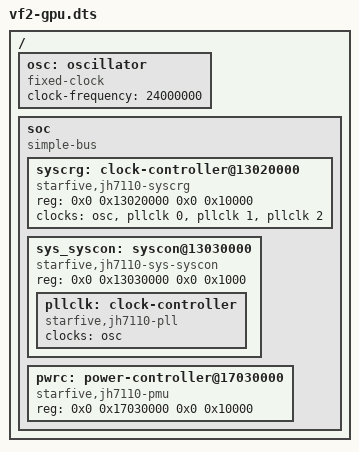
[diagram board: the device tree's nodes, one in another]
/*
 * A device tree in the shape of the VisionFive 2's for the GPU's glue:
 * the oscillator, the SYS clock generator and system control block, and
 * the power management unit.  No GPU node, as on the board.
 */
/dts-v1/;

/ {
	#address-cells = <2>;
	#size-cells = <2>;

	osc: oscillator {
		compatible = "fixed-clock";
		#clock-cells = <0>;
		clock-frequency = <24000000>;
	};

	soc {
		compatible = "simple-bus";
		#address-cells = <2>;
		#size-cells = <2>;
		ranges;

		syscrg: clock-controller@13020000 {
			compatible = "starfive,jh7110-syscrg";
			reg = <0x0 0x13020000 0x0 0x10000>;
			clocks = <&osc>, <&pllclk 0>, <&pllclk 1>, <&pllclk 2>;
			clock-names = "osc", "pll0_out", "pll1_out", "pll2_out";
			#clock-cells = <1>;
			#reset-cells = <1>;
		};

		sys_syscon: syscon@13030000 {
			compatible = "starfive,jh7110-sys-syscon", "syscon", "simple-mfd";
			reg = <0x0 0x13030000 0x0 0x1000>;

			pllclk: clock-controller {
				compatible = "starfive,jh7110-pll";
				clocks = <&osc>;
				#clock-cells = <1>;
			};
		};

		pwrc: power-controller@17030000 {
			compatible = "starfive,jh7110-pmu";
			reg = <0x0 0x17030000 0x0 0x10000>;
			#power-domain-cells = <1>;
		};
	};
};
